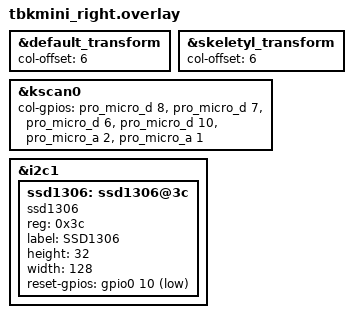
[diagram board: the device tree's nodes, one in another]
/*
 * Copyright (c) 2021 Casey Webster
 *
 * SPDX-License-Identifier: MIT
 */

#include "tbkmini.dtsi"

&default_transform {
	col-offset = <6>;
};

&skeletyl_transform {
	col-offset = <6>;
};

&kscan0 {
	col-gpios
		= <&pro_micro_d 8 (GPIO_ACTIVE_HIGH | GPIO_PULL_DOWN)>
		, <&pro_micro_d 7 (GPIO_ACTIVE_HIGH | GPIO_PULL_DOWN)>
		, <&pro_micro_d  6 (GPIO_ACTIVE_HIGH | GPIO_PULL_DOWN)>
		, <&pro_micro_d  10 (GPIO_ACTIVE_HIGH | GPIO_PULL_DOWN)>
		, <&pro_micro_a  2 (GPIO_ACTIVE_HIGH | GPIO_PULL_DOWN)>
		, <&pro_micro_a  1 (GPIO_ACTIVE_HIGH | GPIO_PULL_DOWN)>
		;
};

// Настройка шины I2C для дисплея
&i2c1 {
    status = "okay";
    ssd1306: ssd1306@3c {
        compatible = "ssd1306";
        reg = <0x3c>;
        label = "SSD1306";
        height = <32>;
        width = <128>;
        reset-gpios = <&gpio0 10 GPIO_ACTIVE_LOW>;
    };
};
